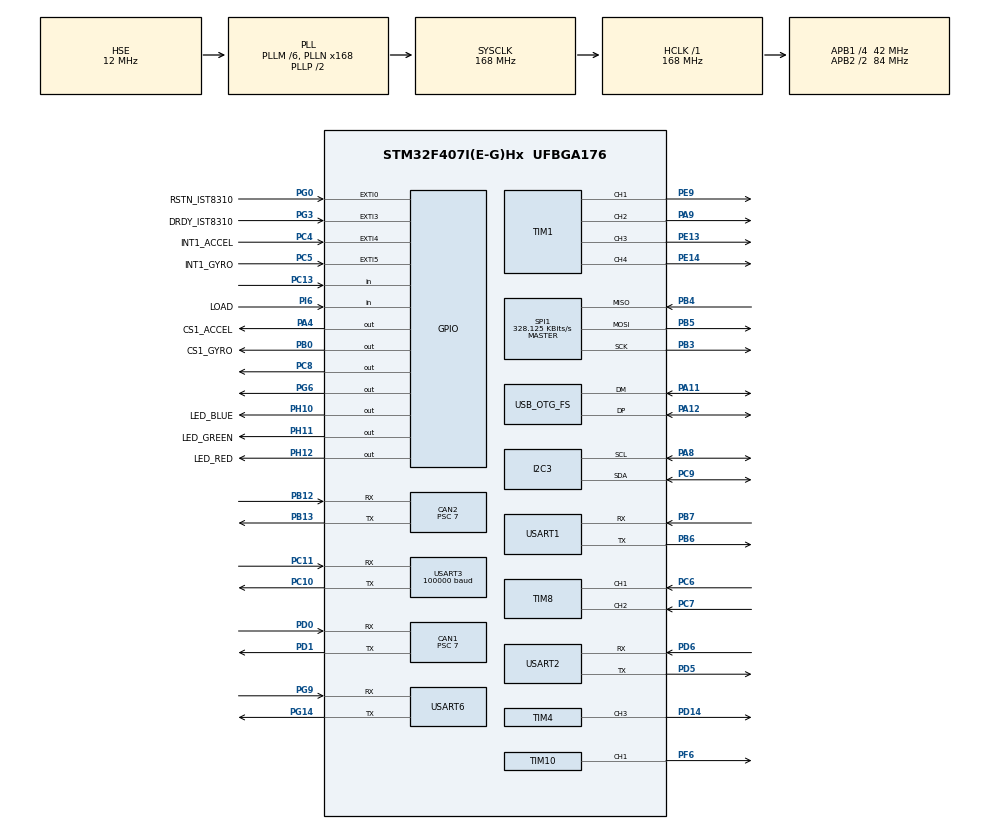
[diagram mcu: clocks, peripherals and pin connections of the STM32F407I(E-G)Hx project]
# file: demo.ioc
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CAN1.ABOM=ENABLE
CAN1.BS1=CAN_BS1_3TQ
CAN1.BS2=CAN_BS2_2TQ
CAN1.CalculateBaudRate=999999
CAN1.CalculateTimeBit=1000
CAN1.CalculateTimeQuantum=166.66666666666669
CAN1.Prescaler=7
CAN1.TXFP=ENABLE
CAN2.ABOM=ENABLE
CAN2.BS1=CAN_BS1_3TQ
CAN2.BS2=CAN_BS2_2TQ
CAN2.CalculateBaudRate=999999
CAN2.CalculateTimeBit=1000
CAN2.CalculateTimeQuantum=166.66666666666669
CAN2.Prescaler=7
CAN2.TXFP=ENABLE
Dma.Request0=SPI1_RX
Dma.Request1=SPI1_TX
Dma.Request2=USART6_TX
Dma.SPI1_RX.0.Direction=DMA_PERIPH_TO_MEMORY
Dma.SPI1_RX.0.FIFOMode=DMA_FIFOMODE_DISABLE
Dma.SPI1_RX.0.Instance=DMA2_Stream2
Dma.SPI1_RX.0.MemDataAlignment=DMA_MDATAALIGN_BYTE
Dma.SPI1_RX.0.MemInc=DMA_MINC_ENABLE
Dma.SPI1_RX.0.Mode=DMA_NORMAL
Dma.SPI1_RX.0.PeriphDataAlignment=DMA_PDATAALIGN_BYTE
Dma.SPI1_RX.0.PeriphInc=DMA_PINC_DISABLE
Dma.SPI1_RX.0.Priority=DMA_PRIORITY_VERY_HIGH
Dma.SPI1_TX.1.Direction=DMA_MEMORY_TO_PERIPH
Dma.SPI1_TX.1.FIFOMode=DMA_FIFOMODE_DISABLE
Dma.SPI1_TX.1.Instance=DMA2_Stream3
Dma.SPI1_TX.1.MemDataAlignment=DMA_MDATAALIGN_BYTE
Dma.SPI1_TX.1.MemInc=DMA_MINC_ENABLE
Dma.SPI1_TX.1.Mode=DMA_NORMAL
Dma.SPI1_TX.1.PeriphDataAlignment=DMA_PDATAALIGN_BYTE
Dma.SPI1_TX.1.PeriphInc=DMA_PINC_DISABLE
Dma.SPI1_TX.1.Priority=DMA_PRIORITY_HIGH
Dma.USART6_TX.2.Direction=DMA_MEMORY_TO_PERIPH
Dma.USART6_TX.2.FIFOMode=DMA_FIFOMODE_DISABLE
Dma.USART6_TX.2.Instance=DMA2_Stream6
Dma.USART6_TX.2.MemDataAlignment=DMA_MDATAALIGN_BYTE
Dma.USART6_TX.2.MemInc=DMA_MINC_ENABLE
Dma.USART6_TX.2.Mode=DMA_NORMAL
Dma.USART6_TX.2.PeriphDataAlignment=DMA_PDATAALIGN_BYTE
Dma.USART6_TX.2.PeriphInc=DMA_PINC_DISABLE
Dma.USART6_TX.2.Priority=DMA_PRIORITY_LOW
FREERTOS.INCLUDE_xTaskGetHandle=1
FREERTOS.Tasks01=defaultTask,0,128,StartDefaultTask,Default,NULL,Dynamic,NULL,NULL;IMUTask,1,384,os_IMUCallback,As weak,NULL,Dynamic,NULL,NULL;LEDTask,-1,128,os_LEDCallback,As weak,NULL,Dynamic,NULL,NULL;MotorTask,0,256,os_MotorCallback,As weak,NULL,Dynamic,NULL,NULL;ChassisTask,0,256,os_ChassisCallback,As weak,NULL,Dynamic,NULL,NULL;RCTask,1,256,os_RCCallback,As weak,NULL,Dynamic,NULL,NULL;ErrorTask,3,128,os_ErrorCallback,As weak,NULL,Dynamic,NULL,NULL;GimbalTask,0,256,os_GimbalCallback,As weak,NULL,Dynamic,NULL,NULL;ShooterTask,0,128,os_ShooterCallback,As weak,NULL,Dynamic,NULL,NULL;VisionTask,0,256,os_VisionCallback,As weak,NULL,Dynamic,NULL,NULL;JudgeTask,0,256,os_JudgeCallback,As weak,NULL,Dynamic,NULL,NULL;DetectTask,0,128,os_DetectCallback,As weak,NULL,Dynamic,NULL,NULL;BeepTask,0,128,os_BeepCallback,As weak,NULL,Dynamic,NULL,NULL;SuperCapTask,0,256,os_SuperCapCallback,As weak,NULL,Dynamic,NULL,NULL
FREERTOS.configMAX_CO_ROUTINE_PRIORITIES=5
Mcu.Family=STM32F4
Mcu.Name=STM32F407I(E-G)Hx
Mcu.Package=UFBGA176
NVIC.CAN1_RX0_IRQn=true\:5\:0\:false\:false\:true\:true\:true\:true
NVIC.CAN1_TX_IRQn=true\:5\:0\:false\:false\:true\:true\:true\:true
NVIC.CAN2_RX0_IRQn=true\:5\:0\:false\:false\:true\:true\:true\:true
NVIC.CAN2_TX_IRQn=true\:5\:0\:false\:false\:true\:true\:true\:true
NVIC.DMA2_Stream2_IRQn=true\:5\:0\:true\:false\:false\:false\:false\:true
NVIC.DMA2_Stream3_IRQn=true\:5\:0\:false\:false\:false\:true\:false\:true
NVIC.DMA2_Stream6_IRQn=true\:5\:0\:false\:false\:true\:true\:false\:true
NVIC.EXTI0_IRQn=true\:5\:0\:true\:false\:true\:true\:true\:true
NVIC.EXTI3_IRQn=true\:5\:0\:true\:false\:true\:true\:true\:true
NVIC.EXTI4_IRQn=true\:5\:0\:true\:false\:true\:true\:true\:true
NVIC.EXTI9_5_IRQn=true\:5\:0\:true\:false\:true\:false\:true\:true
NVIC.PriorityGroup=NVIC_PRIORITYGROUP_4
NVIC.TIM2_IRQn=true\:15\:0\:false\:false\:true\:false\:false\:true
NVIC.TIM5_IRQn=true\:5\:0\:false\:false\:true\:true\:true\:true
NVIC.TimeBase=TIM2_IRQn
NVIC.TimeBaseIP=TIM2
NVIC.USART1_IRQn=true\:5\:0\:false\:false\:true\:true\:true\:true
NVIC.USART2_IRQn=true\:5\:0\:false\:false\:true\:true\:true\:true
NVIC.USART3_IRQn=true\:5\:0\:false\:false\:true\:true\:true\:true
NVIC.USART6_IRQn=true\:5\:0\:false\:false\:true\:true\:true\:true
PA11.Mode=Device_Only
PA11.Signal=USB_OTG_FS_DM
PA12.Mode=Device_Only
PA12.Signal=USB_OTG_FS_DP
PA13.Mode=Serial_Wire
PA13.Signal=SYS_JTMS-SWDIO
PA14.Mode=Serial_Wire
PA14.Signal=SYS_JTCK-SWCLK
PA4.GPIO_Label=CS1_ACCEL
PA4.GPIO_PuPd=GPIO_PULLUP
PA4.GPIO_Speed=GPIO_SPEED_FREQ_HIGH
PA4.PinState=GPIO_PIN_SET
PA4.Signal=GPIO_Output
PA8.Mode=I2C
PA8.Signal=I2C3_SCL
PA9.Signal=S_TIM1_CH2
PB0.GPIO_Label=CS1_GYRO
PB0.GPIO_Speed=GPIO_SPEED_FREQ_HIGH
PB0.PinState=GPIO_PIN_SET
PB0.Signal=GPIO_Output
PB12.Mode=CAN_Activate
PB12.Signal=CAN2_RX
PB13.Mode=CAN_Activate
PB13.Signal=CAN2_TX
PB3.Mode=Full_Duplex_Master
PB3.Signal=SPI1_SCK
PB4.Mode=Full_Duplex_Master
PB4.Signal=SPI1_MISO
PB5.Mode=Full_Duplex_Master
PB5.Signal=SPI1_MOSI
PB6.Mode=Asynchronous
PB6.Signal=USART1_TX
PB7.Mode=Asynchronous
PB7.Signal=USART1_RX
PC10.Mode=Asynchronous
PC10.Signal=USART3_TX
PC11.Mode=Asynchronous
PC11.Signal=USART3_RX
PC13-ANTI_TAMP.Signal=GPIO_Input
PC4.GPIO_Label=INT1_ACCEL
PC4.Signal=GPXTI4
PC5.GPIO_Label=INT1_GYRO
PC5.Signal=GPXTI5
PC6.Signal=S_TIM8_CH1
PC7.Signal=S_TIM8_CH2
PC8.PinState=GPIO_PIN_SET
PC8.Signal=GPIO_Output
PC9.Mode=I2C
PC9.Signal=I2C3_SDA
PD0.Mode=CAN_Activate
PD0.Signal=CAN1_RX
PD1.Mode=CAN_Activate
PD1.Signal=CAN1_TX
PD14.Signal=S_TIM4_CH3
PD5.Mode=Asynchronous
PD5.Signal=USART2_TX
PD6.Mode=Asynchronous
PD6.Signal=USART2_RX
PE13.Signal=S_TIM1_CH3
PE14.Signal=S_TIM1_CH4
PE9.Signal=S_TIM1_CH1
PF6.Signal=S_TIM10_CH1
PG0.GPIO_Label=RSTN_IST8310
PG0.Signal=GPXTI0
PG14.Mode=Asynchronous
PG14.Signal=USART6_TX
PG3.GPIO_Label=DRDY_IST8310
PG3.Signal=GPXTI3
PG6.Signal=GPIO_Output
PG9.Mode=Asynchronous
PG9.Signal=USART6_RX
PH0-OSC_IN.Mode=HSE-External-Oscillator
PH0-OSC_IN.Signal=RCC_OSC_IN
PH1-OSC_OUT.Mode=HSE-External-Oscillator
PH1-OSC_OUT.Signal=RCC_OSC_OUT
PH10.GPIO_Label=LED_BLUE
PH10.GPIO_PuPd=GPIO_PULLDOWN
PH10.Signal=GPIO_Output
PH11.GPIO_Label=LED_GREEN
PH11.GPIO_PuPd=GPIO_PULLDOWN
PH11.Signal=GPIO_Output
PH12.GPIO_Label=LED_RED
PH12.GPIO_PuPd=GPIO_PULLDOWN
PH12.Signal=GPIO_Output
PI6.GPIO_Label=LOAD
PI6.GPIO_PuPd=GPIO_PULLDOWN
PI6.Signal=GPIO_Input
PI7.Signal=S_TIM8_CH3
ProjectManager.HeapSize=0x2000
ProjectManager.StackSize=0x2000
ProjectManager.TargetToolchain=MDK-ARM V5.27
RCC.48MHZClocksFreq_Value=48000000
RCC.AHBFreq_Value=168000000
RCC.APB1CLKDivider=RCC_HCLK_DIV4
RCC.APB1Freq_Value=42000000
RCC.APB1TimFreq_Value=84000000
RCC.APB2CLKDivider=RCC_HCLK_DIV2
RCC.APB2Freq_Value=84000000
RCC.APB2TimFreq_Value=168000000
RCC.CortexFreq_Value=168000000
RCC.HCLKFreq_Value=168000000
RCC.HSE_VALUE=12000000
RCC.HSI_VALUE=16000000
RCC.LSE_VALUE=32768
RCC.PLLM=6
RCC.PLLN=168
RCC.PLLQ=7
RCC.SYSCLKFreq_VALUE=168000000
RCC.SYSCLKSource=RCC_SYSCLKSOURCE_PLLCLK
RCC.VCOOutputFreq_Value=336000000
SH.S_TIM10_CH1.0=TIM10_CH1,PWM Generation1 CH1
SH.S_TIM1_CH1.0=TIM1_CH1,PWM Generation1 CH1
SH.S_TIM1_CH2.0=TIM1_CH2,PWM Generation2 CH2
SH.S_TIM1_CH3.0=TIM1_CH3,PWM Generation3 CH3
SH.S_TIM1_CH4.0=TIM1_CH4,PWM Generation4 CH4
SH.S_TIM4_CH3.0=TIM4_CH3,PWM Generation3 CH3
SH.S_TIM8_CH1.0=TIM8_CH1,Encoder_Interface
SH.S_TIM8_CH2.0=TIM8_CH2,Encoder_Interface
SH.S_TIM8_CH3.0=TIM8_CH3
SPI1.BaudRatePrescaler=SPI_BAUDRATEPRESCALER_256
SPI1.CLKPhase=SPI_PHASE_2EDGE
SPI1.CLKPolarity=SPI_POLARITY_HIGH
SPI1.CalculateBaudRate=328.125 KBits/s
SPI1.Direction=SPI_DIRECTION_2LINES
SPI1.Mode=SPI_MODE_MASTER
SPI1.VirtualType=VM_MASTER
STMicroelectronics.X-CUBE-ALGOBUILD.1.3.0.LibraryCcDSPOoLibraryJjDSPOoLibrary=true
TIM1.Channel-PWM\ Generation1\ CH1=TIM_CHANNEL_1
TIM1.Channel-PWM\ Generation2\ CH2=TIM_CHANNEL_2
TIM1.Channel-PWM\ Generation3\ CH3=TIM_CHANNEL_3
TIM1.Channel-PWM\ Generation4\ CH4=TIM_CHANNEL_4
TIM10.Channel=TIM_CHANNEL_1
TIM10.Period=5000-1
TIM4.Channel-PWM\ Generation3\ CH3=TIM_CHANNEL_3
TIM4.Period=1000-1
TIM4.Prescaler=84-1
TIM5.Period=10-1
TIM5.Prescaler=84-1
USART1.VirtualMode=VM_ASYNC
USART2.VirtualMode=VM_ASYNC
USART3.BaudRate=100000
USART3.Parity=PARITY_EVEN
USART3.VirtualMode=VM_ASYNC
USART3.WordLength=WORDLENGTH_9B
USART6.VirtualMode=VM_ASYNC
USB_OTG_FS.VirtualMode=Device_Only
VP_FREERTOS_VS_CMSIS_V1.Mode=CMSIS_V1
VP_STMicroelectronics.X-CUBE-ALGOBUILD_VS_DSPOoLibraryJjLibrary_1.3.0_1.3.0.Mode=DSPOoLibraryJjLibrary
VP_SYS_VS_tim2.Mode=TIM2
VP_TIM10_VS_ClockSourceINT.Mode=Enable_Timer
VP_TIM5_VS_ClockSourceINT.Mode=Internal
board=custom

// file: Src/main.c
/* USER CODE BEGIN Header */
/**
 ******************************************************************************
 * @file           : main.c
 * @brief          : Main program body
 ******************************************************************************
 * @attention
 *
 * Copyright (c) 2023 STMicroelectronics.
 * All rights reserved.
 *
 * This software is licensed under terms that can be found in the LICENSE file
 * in the root directory of this software component.
 * If no LICENSE file comes with this software, it is provided AS-IS.
 *
 ******************************************************************************
 */
/* USER CODE END Header */
#include "main.h"
#include "cmsis_os.h"
#include "can.h"
#include "dma.h"
#include "i2c.h"
#include "spi.h"
#include "tim.h"
#include "usart.h"
#include "usb_otg.h"
#include "gpio.h"

/* USER CODE BEGIN Includes */
#include "USER_Laser.h"
/* USER CODE END Includes */

void SystemClock_Config(void);
void MX_FREERTOS_Init(void);

int main(void)
{

  /* MCU Configuration--------------------------------------------------------*/

  /* Reset of all peripherals, Initializes the Flash interface and the Systick. */
  HAL_Init();

  /* Configure the system clock */
  SystemClock_Config();

  /* Initialize all configured peripherals */
  MX_GPIO_Init();
  MX_DMA_Init();
  MX_CAN1_Init();
  MX_CAN2_Init();
  MX_I2C3_Init();
  MX_SPI1_Init();
  MX_TIM4_Init();
  MX_TIM5_Init();
  MX_TIM10_Init();
  MX_USART1_UART_Init();
  MX_USART2_UART_Init();
  MX_USART3_UART_Init();
  MX_USART6_UART_Init();
  MX_TIM1_Init();
  MX_USB_OTG_FS_PCD_Init();
  MX_TIM8_Init();
  /* USER CODE BEGIN 2 */
  Laser_Init();
  /* USER CODE END 2 */

  /* Call init function for freertos objects (in freertos.c) */
  MX_FREERTOS_Init();
  /* Start scheduler */
  osKernelStart();

  /* We should never get here as control is now taken by the scheduler */
  /* Infinite loop */
  while (1)
  {

  }
}

void SystemClock_Config(void)
{
  RCC_OscInitTypeDef RCC_OscInitStruct = {0};
  RCC_ClkInitTypeDef RCC_ClkInitStruct = {0};

  /** Configure the main internal regulator output voltage
   */
  __HAL_RCC_PWR_CLK_ENABLE();
  __HAL_PWR_VOLTAGESCALING_CONFIG(PWR_REGULATOR_VOLTAGE_SCALE1);
  /** Initializes the RCC Oscillators according to the specified parameters
   * in the RCC_OscInitTypeDef structure.
   */
  RCC_OscInitStruct.OscillatorType = RCC_OSCILLATORTYPE_HSE;
  RCC_OscInitStruct.HSEState = RCC_HSE_ON;
  RCC_OscInitStruct.PLL.PLLState = RCC_PLL_ON;
  RCC_OscInitStruct.PLL.PLLSource = RCC_PLLSOURCE_HSE;
  RCC_OscInitStruct.PLL.PLLM = 6;
  RCC_OscInitStruct.PLL.PLLN = 168;
  RCC_OscInitStruct.PLL.PLLP = RCC_PLLP_DIV2;
  RCC_OscInitStruct.PLL.PLLQ = 7;
  if (HAL_RCC_OscConfig(&RCC_OscInitStruct) != HAL_OK)
  {
    Error_Handler();
  }
  /** Initializes the CPU, AHB and APB buses clocks
   */
  RCC_ClkInitStruct.ClockType = RCC_CLOCKTYPE_HCLK | RCC_CLOCKTYPE_SYSCLK | RCC_CLOCKTYPE_PCLK1 | RCC_CLOCKTYPE_PCLK2;
  RCC_ClkInitStruct.SYSCLKSource = RCC_SYSCLKSOURCE_PLLCLK;
  RCC_ClkInitStruct.AHBCLKDivider = RCC_SYSCLK_DIV1;
  RCC_ClkInitStruct.APB1CLKDivider = RCC_HCLK_DIV4;
  RCC_ClkInitStruct.APB2CLKDivider = RCC_HCLK_DIV2;

  if (HAL_RCC_ClockConfig(&RCC_ClkInitStruct, FLASH_LATENCY_5) != HAL_OK)
  {
    Error_Handler();
  }
}

void HAL_TIM_PeriodElapsedCallback(TIM_HandleTypeDef *htim)
{
  if (htim->Instance == TIM2)
  {
    HAL_IncTick();
  }
}

void Error_Handler(void)
{
  __disable_irq();
  while (1)
  {
  }
}

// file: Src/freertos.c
/* USER CODE BEGIN Header */
/**
  ******************************************************************************
  * File Name          : freertos.c
  * Description        : Code for freertos applications
  ******************************************************************************
  * @attention
  *
  * Copyright (c) 2023 STMicroelectronics.
  * All rights reserved.
  *
  * This software is licensed under terms that can be found in the LICENSE file
  * in the root directory of this software component.
  * If no LICENSE file comes with this software, it is provided AS-IS.
  *
  ******************************************************************************
  */
/* USER CODE END Header */

#include "FreeRTOS.h"
#include "task.h"
#include "main.h"
#include "cmsis_os.h"

osThreadId defaultTaskHandle;
osThreadId IMUTaskHandle;
osThreadId LEDTaskHandle;
osThreadId MotorTaskHandle;
osThreadId ChassisTaskHandle;
osThreadId RCTaskHandle;
osThreadId ErrorTaskHandle;
osThreadId GimbalTaskHandle;
osThreadId ShooterTaskHandle;
osThreadId VisionTaskHandle;
osThreadId JudgeTaskHandle;
osThreadId DetectTaskHandle;
osThreadId BeepTaskHandle;
osThreadId SuperCapTaskHandle;

void StartDefaultTask(void const * argument);
void os_IMUCallback(void const * argument);
void os_LEDCallback(void const * argument);
void os_MotorCallback(void const * argument);
void os_ChassisCallback(void const * argument);
void os_RCCallback(void const * argument);
void os_ErrorCallback(void const * argument);
void os_GimbalCallback(void const * argument);
void os_ShooterCallback(void const * argument);
void os_VisionCallback(void const * argument);
void os_JudgeCallback(void const * argument);
void os_DetectCallback(void const * argument);
void os_BeepCallback(void const * argument);
void os_SuperCapCallback(void const * argument);

void MX_FREERTOS_Init(void); /* (MISRA C 2004 rule 8.1) */

/* GetIdleTaskMemory prototype (linked to static allocation support) */
void vApplicationGetIdleTaskMemory( StaticTask_t **ppxIdleTaskTCBBuffer, StackType_t **ppxIdleTaskStackBuffer, uint32_t *pulIdleTaskStackSize );

/* USER CODE BEGIN GET_IDLE_TASK_MEMORY */
static StaticTask_t xIdleTaskTCBBuffer;
static StackType_t xIdleStack[configMINIMAL_STACK_SIZE];

void vApplicationGetIdleTaskMemory( StaticTask_t **ppxIdleTaskTCBBuffer, StackType_t **ppxIdleTaskStackBuffer, uint32_t *pulIdleTaskStackSize )
{
  *ppxIdleTaskTCBBuffer = &xIdleTaskTCBBuffer;
  *ppxIdleTaskStackBuffer = &xIdleStack[0];
  *pulIdleTaskStackSize = configMINIMAL_STACK_SIZE;
  /* place for user code */
}
/* USER CODE END GET_IDLE_TASK_MEMORY */

void MX_FREERTOS_Init(void) {

  /* Create the thread(s) */
  /* definition and creation of defaultTask */
  osThreadDef(defaultTask, StartDefaultTask, osPriorityNormal, 0, 128);
  defaultTaskHandle = osThreadCreate(osThread(defaultTask), NULL);

  /* definition and creation of IMUTask */
  osThreadDef(IMUTask, os_IMUCallback, osPriorityAboveNormal, 0, 384);
  IMUTaskHandle = osThreadCreate(osThread(IMUTask), NULL);

  /* definition and creation of LEDTask */
  osThreadDef(LEDTask, os_LEDCallback, osPriorityBelowNormal, 0, 128);
  LEDTaskHandle = osThreadCreate(osThread(LEDTask), NULL);

  /* definition and creation of MotorTask */
  osThreadDef(MotorTask, os_MotorCallback, osPriorityNormal, 0, 256);
  MotorTaskHandle = osThreadCreate(osThread(MotorTask), NULL);

  /* definition and creation of ChassisTask */
  osThreadDef(ChassisTask, os_ChassisCallback, osPriorityNormal, 0, 256);
  ChassisTaskHandle = osThreadCreate(osThread(ChassisTask), NULL);

  /* definition and creation of RCTask */
  osThreadDef(RCTask, os_RCCallback, osPriorityAboveNormal, 0, 256);
  RCTaskHandle = osThreadCreate(osThread(RCTask), NULL);

  /* definition and creation of ErrorTask */
  osThreadDef(ErrorTask, os_ErrorCallback, osPriorityRealtime, 0, 128);
  ErrorTaskHandle = osThreadCreate(osThread(ErrorTask), NULL);

  /* definition and creation of GimbalTask */
  osThreadDef(GimbalTask, os_GimbalCallback, osPriorityNormal, 0, 256);
  GimbalTaskHandle = osThreadCreate(osThread(GimbalTask), NULL);

  /* definition and creation of ShooterTask */
  osThreadDef(ShooterTask, os_ShooterCallback, osPriorityNormal, 0, 128);
  ShooterTaskHandle = osThreadCreate(osThread(ShooterTask), NULL);

  /* definition and creation of VisionTask */
  osThreadDef(VisionTask, os_VisionCallback, osPriorityNormal, 0, 256);
  VisionTaskHandle = osThreadCreate(osThread(VisionTask), NULL);

  /* definition and creation of JudgeTask */
  osThreadDef(JudgeTask, os_JudgeCallback, osPriorityNormal, 0, 256);
  JudgeTaskHandle = osThreadCreate(osThread(JudgeTask), NULL);

  /* definition and creation of DetectTask */
  osThreadDef(DetectTask, os_DetectCallback, osPriorityNormal, 0, 128);
  DetectTaskHandle = osThreadCreate(osThread(DetectTask), NULL);

  /* definition and creation of BeepTask */
  osThreadDef(BeepTask, os_BeepCallback, osPriorityNormal, 0, 128);
  BeepTaskHandle = osThreadCreate(osThread(BeepTask), NULL);

  /* definition and creation of SuperCapTask */
  osThreadDef(SuperCapTask, os_SuperCapCallback, osPriorityNormal, 0, 256);
  SuperCapTaskHandle = osThreadCreate(osThread(SuperCapTask), NULL);

}

void StartDefaultTask(void const * argument)
{
  for(;;)
  {
    osDelay(1);
  }
}

__weak void os_IMUCallback(void const * argument)
{
  for(;;)
  {
    osDelay(1);
  }
}

__weak void os_LEDCallback(void const * argument)
{
  for(;;)
  {
    osDelay(1);
  }
}

__weak void os_MotorCallback(void const * argument)
{
  for(;;)
  {
    osDelay(1);
  }
}

__weak void os_ChassisCallback(void const * argument)
{
  for(;;)
  {
    osDelay(1);
  }
}

__weak void os_RCCallback(void const * argument)
{
  for(;;)
  {
    osDelay(1);
  }
}

__weak void os_ErrorCallback(void const * argument)
{
  for(;;)
  {
    osDelay(1);
  }
}

__weak void os_GimbalCallback(void const * argument)
{
  for(;;)
  {
    osDelay(1);
  }
}

__weak void os_ShooterCallback(void const * argument)
{
  for(;;)
  {
    osDelay(1);
  }
}

__weak void os_VisionCallback(void const * argument)
{
  for(;;)
  {
    osDelay(1);
  }
}

__weak void os_JudgeCallback(void const * argument)
{
  for(;;)
  {
    osDelay(1);
  }
}

__weak void os_DetectCallback(void const * argument)
{
  for(;;)
  {
    osDelay(1);
  }
}

__weak void os_BeepCallback(void const * argument)
{
  for(;;)
  {
    osDelay(1);
  }
}

__weak void os_SuperCapCallback(void const * argument)
{
  for(;;)
  {
    osDelay(1);
  }
}
